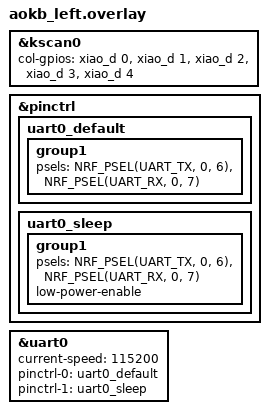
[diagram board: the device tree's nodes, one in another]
#include "aokb.dtsi" // Notice that the main dtsi files are included in the overlay.

&kscan0 {
    col-gpios
        = <&xiao_d 0 GPIO_ACTIVE_HIGH> // col1 in the schematic
        , <&xiao_d 1 GPIO_ACTIVE_HIGH> // col2 in the schematic
        , <&xiao_d 2 GPIO_ACTIVE_HIGH> // col3 in the schematic
        , <&xiao_d 3 GPIO_ACTIVE_HIGH> // col4 in the schematic
        , <&xiao_d 4 GPIO_ACTIVE_HIGH> // col5 in the schematic
        ;
};

&pinctrl {
    uart0_default: uart0_default {
        group1 {
            psels = <NRF_PSEL(UART_TX, 0, 6)>,
                    <NRF_PSEL(UART_RX, 0, 7)>;
        };
    };

    uart0_sleep: uart0_sleep {
        group1 {
            psels = <NRF_PSEL(UART_TX, 0, 6)>,
                    <NRF_PSEL(UART_RX, 0, 7)>;
            low-power-enable;
        };
    };
};

&uart0 {
    status = "okay";
    current-speed = <115200>;
    pinctrl-0 = <&uart0_default>;
    pinctrl-1 = <&uart0_sleep>;
    pinctrl-names = "default", "sleep";
};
